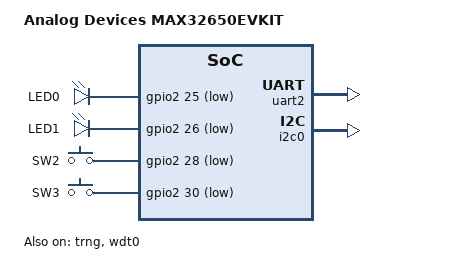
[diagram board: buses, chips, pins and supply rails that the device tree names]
/*
 * Copyright (c) 2023-2024 Analog Devices, Inc.
 *
 * SPDX-License-Identifier: Apache-2.0
 */

/dts-v1/;

#include <adi/max32/max32650.dtsi>
#include <adi/max32/max32650-pinctrl.dtsi>
#include <zephyr/dt-bindings/gpio/adi-max32-gpio.h>
#include <zephyr/dt-bindings/input/input-event-codes.h>

/ {
	model = "Analog Devices MAX32650EVKIT";
	compatible = "adi,max32650evkit";

	chosen {
		zephyr,console = &uart0;
		zephyr,shell-uart = &uart0;
		zephyr,sram = &sram3;
		zephyr,flash = &flash0;
	};

	leds {
		compatible = "gpio-leds";
		red_led: led_0 {
			gpios = <&gpio2 25 GPIO_ACTIVE_LOW>;
			label = "LED0";
		};
		green_led: led_1 {
			gpios = <&gpio2 26 GPIO_ACTIVE_LOW>;
			label = "LED1";
		};
	};

	buttons {
		compatible = "gpio-keys";
		pb0: pb0 {
			gpios = <&gpio2 28 (GPIO_PULL_UP | GPIO_ACTIVE_LOW)>;
			label = "SW2";
			zephyr,code = <INPUT_KEY_0>;
		};
		pb1: pb1 {
			gpios = <&gpio2 30 (GPIO_PULL_UP | GPIO_ACTIVE_LOW)>;
			label = "SW3";
			zephyr,code = <INPUT_KEY_1>;
		};
	};

	aliases {
		led0 = &red_led;
		led1 = &green_led;
		sw0 = &pb0;
		sw1 = &pb1;
		watchdog0 = &wdt0;
	 };
};

&clk_ipo {
	status = "okay";
};

&clk_ibro {
	status = "okay";
};

&gpio0 {
	status = "okay";
};

&gpio1 {
	status = "okay";
};

&gpio2 {
	status = "okay";
};

&gpio3 {
	status = "okay";
};

&uart2 {
	status = "okay";
};

&trng {
	status = "okay";
};

&i2c0 {
	status = "okay";
};

&dma0 {
	status = "okay";
};

&wdt0 {
	status = "okay";
};
